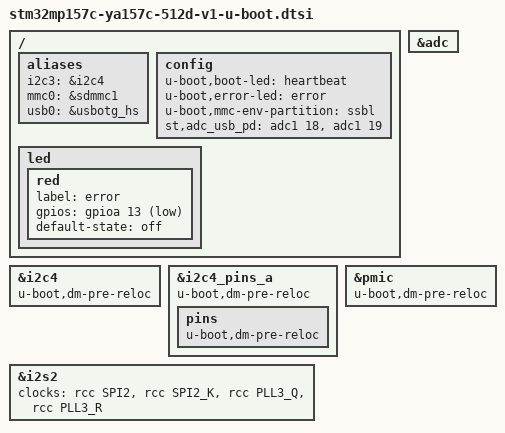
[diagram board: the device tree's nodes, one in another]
// SPDX-License-Identifier: GPL-2.0+ OR BSD-3-Clause
/*
 * Copyright : STMicroelectronics 2018
 */

#include <dt-bindings/clock/stm32mp1-clksrc.h>
#include "stm32mp15-u-boot.dtsi"
#include "stm32mp15-ddr3-2x2Gb-1066-binG.dtsi"

/ {
	aliases {
		i2c3 = &i2c4;
		mmc0 = &sdmmc1;
		usb0 = &usbotg_hs;
	};
	config {
		u-boot,boot-led = "heartbeat";
		u-boot,error-led = "error";
		u-boot,mmc-env-partition = "ssbl";
		st,adc_usb_pd = <&adc1 18>, <&adc1 19>;
		
	};
	led {
		red {
			label = "error";
			gpios = <&gpioa 13 GPIO_ACTIVE_LOW>;
			default-state = "off";
			status = "okay";
		};
	};
};

&adc {
	status = "okay";
};


//&clk_hse {
//	st,digbypass;
//};

&i2c4 {
	u-boot,dm-pre-reloc;
};

&i2c4_pins_a {
	u-boot,dm-pre-reloc;
	pins {
		u-boot,dm-pre-reloc;
	};
};

&i2s2 {
	clocks = <&rcc SPI2>, <&rcc SPI2_K>, <&rcc PLL3_Q>, <&rcc PLL3_R>;
};

&pmic {
	u-boot,dm-pre-reloc;
};

